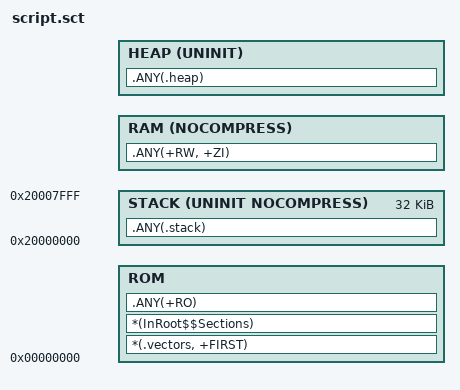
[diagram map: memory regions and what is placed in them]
/*******************************************************************************
@file     lm4f120h5qr.sct
@author   Rajmund Szymanski
@date     19.05.2016
@brief    Scatter file for LM4F120H5QR device with 256KB FLASH and 32KB RAM
*******************************************************************************/

FLASH 0x00000000 0x00040000
{
	ROM +0
	{
		*(.vectors, +FIRST)
		*(InRoot$$Sections)
		.ANY(+RO)
	}

	STACK 0x20000000 UNINIT NOCOMPRESS 0x00008000
	{
		.ANY(.stack)
	}

	RAM ALIGNEXPR(+0, 8) NOCOMPRESS
	{
		.ANY(+RW, +ZI)
	}

	HEAP ALIGNEXPR(+0, 8) UNINIT
	{
		.ANY(.heap)
	}
}
